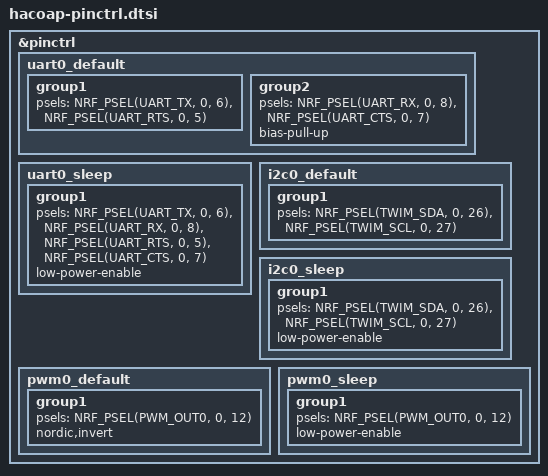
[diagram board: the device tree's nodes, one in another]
/*
 * Copyright (c) 2022 Nordic Semiconductor
 * SPDX-License-Identifier: Apache-2.0
 */

&pinctrl {

	/* UART 0 is broken out on connector J4, pins 6 (TX) and 7 (RX) 
	*/
	uart0_default: uart0_default {
		group1 {
			psels = <NRF_PSEL(UART_TX, 0, 6)>,
				<NRF_PSEL(UART_RTS, 0, 5)>;
		};
		group2 {
			psels = <NRF_PSEL(UART_RX, 0, 8)>,
				<NRF_PSEL(UART_CTS, 0, 7)>;
			bias-pull-up;
		};
	};
	uart0_sleep: uart0_sleep {
		group1 {
			psels = <NRF_PSEL(UART_TX, 0, 6)>,
				<NRF_PSEL(UART_RX, 0, 8)>,
				<NRF_PSEL(UART_RTS, 0, 5)>,
				<NRF_PSEL(UART_CTS, 0, 7)>;
			low-power-enable;
		};
	};

	/* i2c0 is physically connected to the following devices: 
			- MAX17048 fuel gauge (U1)
			- HDC1080D temperature/hunmidty sensor (U6)
			- VL53L0CX time-of-flight sensor (U7)
			- LSM6DSMT IMU sensor (U8)
	*/
	i2c0_default: i2c0_default {
		group1 {
			psels = <NRF_PSEL(TWIM_SDA, 0, 26)>,
				<NRF_PSEL(TWIM_SCL, 0, 27)>;
		};
	};
	i2c0_sleep: i2c0_sleep {
		group1 {
			psels = <NRF_PSEL(TWIM_SDA, 0, 26)>,
				<NRF_PSEL(TWIM_SCL, 0, 27)>;
			low-power-enable;
		};
	};

	/* PWM0 is connected to buzzer BZ1 
	*/
	pwm0_default: pwm0_default {
		group1 {
			psels = <NRF_PSEL(PWM_OUT0, 0, 12)>;
			nordic,invert;
		};
	};
	pwm0_sleep: pwm0_sleep {
		group1 {
			psels = <NRF_PSEL(PWM_OUT0, 0, 12)>;
			low-power-enable;
		};
	};

};

